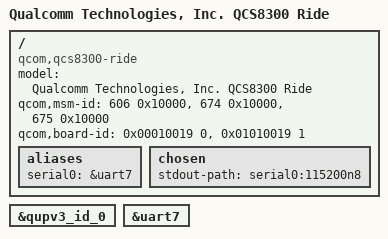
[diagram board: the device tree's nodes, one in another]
// SPDX-License-Identifier: BSD-3-Clause
/*
 * Copyright (c) 2024 Qualcomm Innovation Center, Inc. All rights reserved.
 */

/dts-v1/;

#include "qcs8300.dtsi"
/ {
	model = "Qualcomm Technologies, Inc. QCS8300 Ride";
	compatible = "qcom,qcs8300-ride", "qcom,qcs8275", "qcom,qcs8300";

	qcom,msm-id = <606 0x10000>, <674 0x10000>, <675 0x10000>;
	qcom,board-id = <0x00010019 0>, <0x01010019 1>;

	aliases {
		serial0 = &uart7;
	};

	chosen {
		stdout-path = "serial0:115200n8";
	};
};

&qupv3_id_0 {
	status = "okay";
};

&uart7 {
	status = "okay";
};
